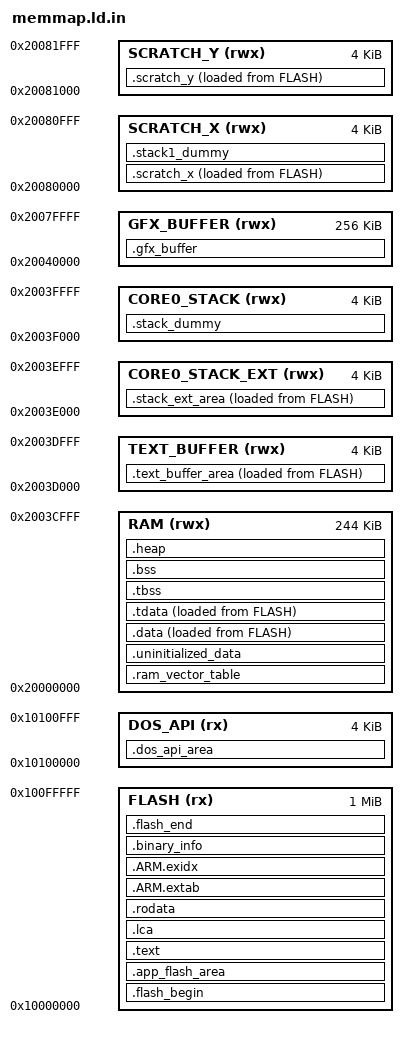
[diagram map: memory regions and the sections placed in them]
/* Based on GCC ARM embedded samples.
   Defines the following symbols for use by code:
    __exidx_start
    __exidx_end
    __etext
    __data_start__
    __preinit_array_start
    __preinit_array_end
    __init_array_start
    __init_array_end
    __fini_array_start
    __fini_array_end
    __data_end__
    __bss_start__
    __bss_end__
    __end__
    end
    __HeapLimit
    __StackLimit
    __StackTop
    __stack (== StackTop)
*/

MEMORY
{
    FLASH(rx) : ORIGIN = 0x10000000, LENGTH = 1M
    DOS_API(rx) : ORIGIN = 0x10000000 + 1M, LENGTH = 4096
    
    /* SRAM0..3 blocks */
    RAM(rwx) : ORIGIN = 0x20000000, LENGTH = 244k /* main RAM, core0 stack protected */
    TEXT_BUFFER(rwx) : ORIGIN = 0x2003D000, LENGTH = 4k  /* OSD fast SRAM, core0 stack extention (partly protected) */
    CORE0_STACK_EXT(rwx) : ORIGIN = 0x2003E000, LENGTH = 4k  /* CONFIG-only scratch; reclaimed as FatFs cache after init */
    CORE0_STACK(rwx) : ORIGIN = 0x2003f000, LENGTH = 4k  /* core0 stack; reclaimed as FatFs cache after direct-QSPI SP relocation */

    /* SRAM4..7 blocks */
    GFX_BUFFER(rwx) : ORIGIN = 0x20040000, LENGTH = 256k  /* complete SRAM4..7 striped group */

    /* SRAM8 block for core1 stack and several "hot" variables */
    SCRATCH_X(rwx) : ORIGIN = 0x20080000, LENGTH = 4k

    /* SRAM9 block for "hot" variables */
    SCRATCH_Y(rwx) : ORIGIN = 0x20081000, LENGTH = 4k
}

ENTRY(_entry_point)

SECTIONS
{
    .flash_begin : {
        __flash_binary_start = .;
        __logical_binary_start = .;
        KEEP(*(.vectors))
        KEEP(*(.binary_info_header))
        __binary_info_header_end = .;
        KEEP(*(.embedded_block))     /* тут должен лежать IMAGE_DEF */
        __embedded_block_end = .;
        . = ALIGN(4);
    } > FLASH

    .app_flash_area : {
        __app_flash_area__ = .;
        KEEP (*(.app_flash))
        __app_flash_area_end__ = .;
    } > FLASH

    .dos_api_area : {
        __dos_api_area__ = .;
        KEEP (*(.dos_api))
        __dos_api_area_end__ = .;
    } > DOS_API

    .stack_ext_area : {
        __stack_ext_area__ = .;
        KEEP (*(.core0_stack_ext))
        KEEP (*(.core0_stack_ext.*))
        __stack_ext_area_end__ = .;
    } > CORE0_STACK_EXT AT > FLASH
    /* Init source for .stack_ext_area, mirrors __scratch_x_source__. Copied to
       RAM once at boot (see main()), so `= {0}` / initialized variables placed
       in .core0_stack_ext behave like normal .data instead of powering up with
       garbage. */
    __stack_ext_area_source__ = LOADADDR(.stack_ext_area);

    .text_buffer_area : {
        __text_buffer_area__ = .;
        KEEP (*(.text_buffer))
        KEEP (*(.text_buffer.*))
        __text_buffer_area_end__ = .;
    } > TEXT_BUFFER AT > FLASH
    /* Init source for .text_buffer, mirrors __scratch_x_source__. Copied to
       RAM once at boot (see main()), so `= {0}` / initialized variables placed
       in .text_buffer behave like normal .data instead of powering up with
       garbage. */
    __text_buffer_area_source__ = LOADADDR(.text_buffer_area);

    .text : {
        KEEP (*(.reset))

        /* TODO revisit this now memset/memcpy/float in ROM */
        /* bit of a hack right now to exclude all floating point and time critical (e.g. memset, memcpy) code from
         * FLASH ... we will include any thing excluded here in .data below by default */
        *(.init)
        *libgcc.a:cmse_nonsecure_call.o
        *(.fini)

        /* Pull all c'tors into .text */
        *crtbegin.o(.ctors)
        *crtbegin?.o(.ctors)
        *(EXCLUDE_FILE(*crtend?.o *crtend.o) .ctors)
        *(SORT(.ctors.*))
        *(.ctors)
        /* Followed by destructors */
        *crtbegin.o(.dtors)
        *crtbegin?.o(.dtors)
        *(EXCLUDE_FILE(*crtend?.o *crtend.o) .dtors)
        *(SORT(.dtors.*))
        *(.dtors)

        . = ALIGN(4);
        /* preinit data */
        PROVIDE_HIDDEN (__preinit_array_start = .);
        KEEP(*(SORT(.preinit_array.*)))
        KEEP(*(.preinit_array))
        PROVIDE_HIDDEN (__preinit_array_end = .);

        . = ALIGN(4);
        /* init data */
        PROVIDE_HIDDEN (__init_array_start = .);
        KEEP(*(SORT(.init_array.*)))
        KEEP(*(.init_array))
        PROVIDE_HIDDEN (__init_array_end = .);

        . = ALIGN(4);
        /* finit data */
        PROVIDE_HIDDEN (__fini_array_start = .);
        *(SORT(.fini_array.*))
        *(.fini_array)
        PROVIDE_HIDDEN (__fini_array_end = .);

        *(.eh_frame*)
        . = ALIGN(4);
    } > FLASH
    
    /* TODO: analize what may be moved higher */
    .lca : {
        *(EXCLUDE_FILE(*libgcc.a: *libc.a:*lib_a-mem*.o *libm.a: *emu8950.c.obj *slot_render.cpp.obj) .text*)
    } > FLASH

    .rodata : {
        *(EXCLUDE_FILE(*libgcc.a: *libc.a:*lib_a-mem*.o *libm.a: *emu8950.c.obj *slot_render.cpp.obj) .rodata*)
        *(.srodata*)
        . = ALIGN(4);
        *(SORT_BY_ALIGNMENT(SORT_BY_NAME(.flashdata*)))
        . = ALIGN(4);
    } > FLASH

    .ARM.extab :
    {
        *(.ARM.extab* .gnu.linkonce.armextab.*)
    } > FLASH

    __exidx_start = .;
    .ARM.exidx :
    {
        *(.ARM.exidx* .gnu.linkonce.armexidx.*)
    } > FLASH
    __exidx_end = .;

    /* Machine inspectable binary information */
    . = ALIGN(4);
    __binary_info_start = .;
    .binary_info :
    {
        KEEP(*(.binary_info.keep.*))
        *(.binary_info.*)
    } > FLASH
    __binary_info_end = .;
    . = ALIGN(4);

    .ram_vector_table (NOLOAD): {
        *(.ram_vector_table)
    } > RAM

    .uninitialized_data (NOLOAD): {
        . = ALIGN(4);
        *(.uninitialized_data*)
    } > RAM

    .data : {
        __data_start__ = .;
        *(vtable)

        *(.time_critical*)

        /* remaining .text and .rodata; i.e. stuff we exclude above because we want it in RAM */
        *(.text*)
        . = ALIGN(4);
        *(.rodata*)
        . = ALIGN(4);

        *(.data*)
        *(.sdata*)

        . = ALIGN(4);
        *(.after_data.*)
        . = ALIGN(4);
        /* preinit data */
        PROVIDE_HIDDEN (__mutex_array_start = .);
        KEEP(*(SORT(.mutex_array.*)))
        KEEP(*(.mutex_array))
        PROVIDE_HIDDEN (__mutex_array_end = .);

        *(.jcr)
        . = ALIGN(4);
    } > RAM AT> FLASH

    .tdata : {
        . = ALIGN(4);
		*(.tdata .tdata.* .gnu.linkonce.td.*)
        /* All data end */
        __tdata_end = .;
    } > RAM AT> FLASH
    PROVIDE(__data_end__ = .);

    /* __etext is (for backwards compatibility) the name of the .data init source pointer (...) */
    __etext = LOADADDR(.data);

    /* Keep the 256 KiB framebuffer on the complete upper main-SRAM
     * striped group (physical SRAM4..7). This must precede the generic
     * .bss wildcard below. */
    .gfx_buffer (NOLOAD) : {
        __gfx_buffer_start__ = .;
        KEEP(*(.bss.gfx_buffer))
        __gfx_video_end__ = .;
        KEEP(*(.bss.gfx_buffer.*))
        __gfx_buffer_end__ = .;
    } > GFX_BUFFER

    .tbss (NOLOAD) : {
        . = ALIGN(4);
        __bss_start__ = .;
        __tls_base = .;
        *(.tbss .tbss.* .gnu.linkonce.tb.*)
        *(.tcommon)

        __tls_end = .;
    } > RAM

    .bss (NOLOAD) : {
        . = ALIGN(4);
        __tbss_end = .;

        *(SORT_BY_ALIGNMENT(SORT_BY_NAME(.bss*)))
        *(COMMON)
        PROVIDE(__global_pointer$ = . + 2K);
        *(.sbss*)
        . = ALIGN(4);
        __bss_end__ = .;
    } > RAM

    .heap (NOLOAD):
    {
        __end__ = .;
        end = __end__;
        KEEP(*(.heap*))
    } > RAM
    /* historically on GCC sbrk was growing past __HeapLimit to __StackLimit, however
       to be more compatible, we now set __HeapLimit explicitly to where the end of the heap is */
    __HeapLimit = ORIGIN(RAM) + LENGTH(RAM);

    /* Start and end symbols must be word-aligned */
    .scratch_x : {
        __scratch_x_start__ = .;
        *(.scratch_x.*)
        . = ALIGN(4);
        __scratch_x_end__ = .;
    } > SCRATCH_X AT > FLASH
    __scratch_x_source__ = LOADADDR(.scratch_x);

    .scratch_y : {
        __scratch_y_start__ = .;
        *(.scratch_y.*)
        . = ALIGN(4);
        __scratch_y_end__ = .;
    } > SCRATCH_Y AT > FLASH
    __scratch_y_source__ = LOADADDR(.scratch_y);

    /* .stack*_dummy section doesn't contains any symbols. It is only
     * used for linker to calculate size of stack sections, and assign
     * values to stack symbols later
     *
     * stack1 section may be empty/missing if platform_launch_core1 is not used */

    /* Core 1 keeps the Pico SDK layout in SCRATCH_X.
     * Core 0 has a dedicated 4 KiB SRAM region CORE0_STACK.
     */
    .stack1_dummy (NOLOAD):
    {
        *(.stack1*)
    } > SCRATCH_X
    .stack_dummy (NOLOAD):
    {
        KEEP(*(.stack*))
    } > CORE0_STACK

    .flash_end : {
        KEEP(*(.embedded_end_block*))
        PROVIDE(__flash_binary_end = .);
    } > FLASH =0xaa

    /* stack limit is poorly named, but historically is maximum heap ptr */
    __StackLimit = ORIGIN(RAM) + LENGTH(RAM);

    /* Core 1 stack remains entirely in SCRATCH_X. */
    __StackOneTop = ORIGIN(SCRATCH_X) + LENGTH(SCRATCH_X);
    __StackOneBottom = __StackOneTop - SIZEOF(.stack1_dummy);

    /* Core 0 stack lives entirely in the dedicated CORE0_STACK region. */
    __StackTop = ORIGIN(CORE0_STACK) + LENGTH(CORE0_STACK);
    __StackBottom = __StackTop - SIZEOF(.stack_dummy);
    __Core0StackExtRegionStart = ORIGIN(CORE0_STACK_EXT);
    __Core0StackRegionStart = ORIGIN(CORE0_STACK);
    __Core0StackRegionEnd = ORIGIN(CORE0_STACK) + LENGTH(CORE0_STACK);
    PROVIDE(__stack = __StackTop);

    ASSERT(SIZEOF(.stack_dummy) <= LENGTH(CORE0_STACK), "core0 stack exceeds CORE0_STACK")
    ASSERT(ORIGIN(CORE0_STACK_EXT) + LENGTH(CORE0_STACK_EXT) == ORIGIN(CORE0_STACK), "CORE0_STACK_EXT and CORE0_STACK must be contiguous")
    ASSERT(SIZEOF(.stack1_dummy) <= LENGTH(SCRATCH_X), "core1 stack exceeds SCRATCH_X")
    ASSERT(SIZEOF(.gfx_buffer) == @GFX_BUFFER_EXPECTED_SIZE@,
           "gfx_buffer has unexpected size")

    /* picolibc and LLVM */
    PROVIDE (__heap_start = __end__);
    PROVIDE (__heap_end = __HeapLimit);
    PROVIDE( __tls_align = MAX(ALIGNOF(.tdata), ALIGNOF(.tbss)) );
    PROVIDE( __tls_size_align = (__tls_size + __tls_align - 1) & ~(__tls_align - 1));
    PROVIDE( __arm32_tls_tcb_offset = MAX(8, __tls_align) );

    /* llvm-libc */
    PROVIDE (_end = __end__);
    PROVIDE (__llvm_libc_heap_limit = __HeapLimit);

    /* Check if data + heap + stack exceeds RAM limit */
    ASSERT(__StackLimit >= __HeapLimit, "region RAM overflowed")

    ASSERT( __binary_info_header_end - __logical_binary_start <= 1024, "Binary info must be in first 1024 bytes of the binary")
    ASSERT( __embedded_block_end - __logical_binary_start <= 4096, "Embedded block must be in first 4096 bytes of the binary")

    /* todo assert on extra code */
}

